# M451_v1 register map
File version: 1.0
M451_v1 SVD file
Registers are 32-bit, read-write, reset 0x0 unless marked. A register's access mark holds for its fields unless they carry their own. Offsets are from the block's base; lines under a group give offsets from that group; [hi:lo] are bit positions; {n}, {i} and the like mark numbered series; 'fields as' and 'values as' point back to an identical list; <NAME> marks a mode.

## Memory map
0x40000000 SYS blocks up to offset 0x404 — SYS Register Map
0x40000200 CLK blocks up to offset 0x80 — CLK Register Map
0x40000300 NMI size 0x8 — NMI Register Map
0x40004000 GPIO blocks up to offset 0x960 — GPIO Register Map
0x40008000 DSCT_CTL blocks up to offset 0xB4 — PDMA Register Map
0x40008000 PDMA blocks up to offset 0x48C — PDMA Register Map
0x40008004 DSCT_SA blocks up to offset 0xB4 — PDMA Register Map
0x40008008 DSCT_DA blocks up to offset 0xB4 — PDMA Register Map
0x4000800C DSCT_NEXT blocks up to offset 0xB4 — PDMA Register Map
0x400080C0 CURSCAT size 0x30 — PDMA Register Map
0x40009000 USBH blocks up to offset 0x208 — USBH Register Map
0x4000C000 FMC blocks up to offset 0xC8 — FMC Register Map
0x40010000 EBI blocks up to offset 0x18 — EBI Register Map
0x40031000 CRC size 0x10 — CRC Register Map
0x40040000 WDT size 0x8 — WDT Register Map
0x40040100 WWDT size 0x10 — WWDT Register Map
0x40041000 RTC blocks up to offset 0x110 — RTC Register Map
0x40043000 EADC blocks up to offset 0x110 — EADC Register Map
0x40045000 ACMP01 size 0x10 — ACMP Register Map
0x40047000 DAC size 0x18 — DAC Register Map
0x4004D000 OTG size 0x14 — OTG Register Map
0x40050000 TMR01 blocks up to offset 0x3C — TMR Register Map
0x40051000 TMR23 blocks up to offset 0x3C — TMR Register Map
0x40058000 PWM0 blocks up to offset 0x350 — PWM Register Map
0x40059000 PWM1 blocks up to offset 0x350 — PWM Register Map
0x40060000 SPI0 blocks up to offset 0x6C — SPI Register Map
0x40061000 SPI1 blocks up to offset 0x6C — SPI Register Map
0x40062000 SPI2 blocks up to offset 0x6C — SPI Register Map
0x40070000 UART0 size 0x3C — UART Register Map
0x40071000 UART1 size 0x3C — UART Register Map
0x40072000 UART2 size 0x34 — UART Register Map
0x40073000 UART3 size 0x34 — UART Register Map
0x40080000 I2C0 blocks up to offset 0x60 — I2C Register Map
0x40081000 I2C1 blocks up to offset 0x60 — I2C Register Map
0x40090000 SC size 0x40 — SC Register Map
0x400A0000 CAN blocks up to offset 0x170 — CAN Register Map
0x400C0000 USBD blocks up to offset 0x580 — USBD Register Map
0xE000E000 SCS blocks up to offset 0xD24 — SYST_SCR Register Map
0xE000E100 NVIC blocks up to offset 0xE04 — NVIC Register Map

## Interrupts
53 USBD_INT (USBD)

## NVIC — NVIC Register Map
Base 0xE000E100
0x00 NVIC_ISER1 — IRQ0 ~ IRQ63 Set-enable Control Register
  [31:0] SETENA — Interrupt Set Enable Bit. The NVIC_ISER0-NVIC_ISER3 registers enable interrupts, and show which interrupts are enabled. Write Operation:
    0=No effect. Interrupt Disabled; 1=Interrupt Enabled
0x04 NVIC_ISER2 — IRQ0 ~ IRQ63 Set-enable Control Register
  fields as NVIC_ISER1
0x80 NVIC_ICER1 — IRQ0 ~ IRQ63 Clear-enable Control Register
  [31:0] CALENA — Interrupt Clear Enable Bit. The NVIC_ICER0-NVIC_ICER3 registers disable interrupts, and show which interrupts are enabled. Write Operation:
    0=No effect. Interrupt Disabled; 1=Interrupt Disabled. Interrupt Enabled
0x84 NVIC_ICER2 — IRQ0 ~ IRQ63 Clear-enable Control Register
  fields as NVIC_ICER1
0x100 NVIC_ISPR1 — IRQ0 ~ IRQ63 Set-pending Control Register
  [31:0] SETPEND — Interrupt Set-pending. The NVIC_ISPR0-NVIC_ISPR3 registers force interrupts into the pending state, and show which interrupts are pending. Write Operation:
    0=No effect. Interrupt is not pending; 1=Changes interrupt state to pending. Interrupt is pending
0x104 NVIC_ISPR2 — IRQ0 ~ IRQ63 Set-pending Control Register
  fields as NVIC_ISPR1
0x180 NVIC_ICPR1 — IRQ0 ~ IRQ63 Clear-pending Control Register
  [31:0] CALPEND — Interrupt Clear-pending. The NVIC_ICPR0-NVIC_ICPR2 registers remove the pending state from interrupts, and show which interrupts are pending. Write Operation:
    0=No effect. Interrupt is not pending; 1=Removes pending state an interrupt. Interrupt is pending
0x184 NVIC_ICPR2 — IRQ0 ~ IRQ63 Clear-pending Control Register
  fields as NVIC_ICPR1
0x200 NVIC_IABR1 — IRQ0 ~ IRQ63 Active Bit Register
  [31:0] ACTIVE — Interrupt Active Flags. The NVIC_IABR0-NVIC_IABR3 registers indicate which interrupts are active.
    0=interrupt not active; 1=interrupt active
0x204 NVIC_IABR2 — IRQ0 ~ IRQ63 Active Bit Register
  fields as NVIC_IABR1
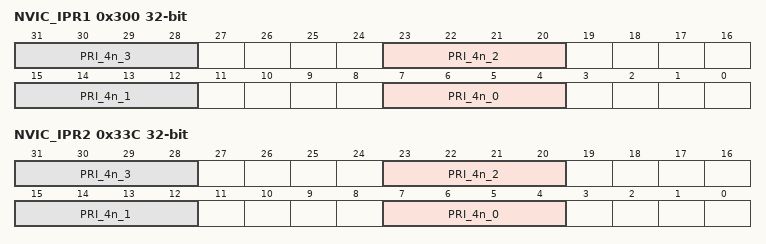
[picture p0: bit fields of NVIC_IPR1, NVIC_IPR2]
0x300 NVIC_IPR1 — IRQ0 ~ IRQ63 Priority Control Register
  [8n+7:8n+4] PRI_4n_{n} (n=0..3) — Priority of IRQ_4n+{n} '0' denotes the highest priority and '15' denotes the lowest priority
0x33C NVIC_IPR2 — IRQ0 ~ IRQ63 Priority Control Register
  fields as NVIC_IPR1
0xE00 STIR — Software Trigger Interrupt Registers
  [8:0] INTID — Interrupt ID. Write to the STIR To Generate An Interrupt from Software. When the USERSETMPEND bit in the SCR is set to 1, unprivileged software can access the STIR. Interrupt ID of the interrupt to trigger, in the range 0-63. For example, a value of 0x03 specifies interrupt IRQ3.
